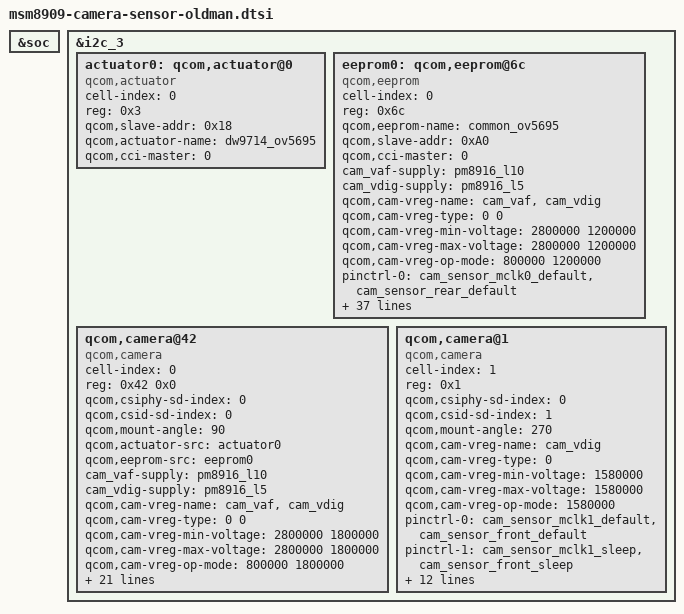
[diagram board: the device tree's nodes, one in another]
/*
 * Copyright (c) 2014-2015, The Linux Foundation. All rights reserved.
 *
 * This program is free software; you can redistribute it and/or modify
 * it under the terms of the GNU General Public License version 2 and
 * only version 2 as published by the Free Software Foundation.
 *
 * This program is distributed in the hope that it will be useful,
 * but WITHOUT ANY WARRANTY; without even the implied warranty of
 * MERCHANTABILITY or FITNESS FOR A PARTICULAR PURPOSE.  See the
 * GNU General Public License for more details.
 */

&soc {
};

&i2c_3 {

	actuator0: qcom,actuator@0 {
		cell-index = <0>;
		reg = <0x3>;
		qcom,slave-addr = <0x18>;
		compatible = "qcom,actuator";
		qcom,actuator-name = "dw9714_ov5695";
		qcom,cci-master = <0>;
	
	};

	eeprom0: qcom,eeprom@6c{
		cell-index = <0>;
		reg = <0x6c>;
		qcom,eeprom-name = "common_ov5695";
		compatible = "qcom,eeprom";
		qcom,slave-addr = <0xA0>;
		qcom,cci-master = <0>;	
			cam_vaf-supply = <&pm8916_l10>;
			cam_vdig-supply = <&pm8916_l5>; 	
			qcom,cam-vreg-name = "cam_vaf","cam_vdig";
			qcom,cam-vreg-type = <0  0>;
			qcom,cam-vreg-min-voltage = < 2800000 1200000 >;
			qcom,cam-vreg-max-voltage = < 2800000 1200000 >;
			qcom,cam-vreg-op-mode = <800000  1200000>;
			pinctrl-names = "cam_default", "cam_suspend";
			pinctrl-0 = <&cam_sensor_mclk0_default
					&cam_sensor_rear_default>;
			pinctrl-1 = <&cam_sensor_mclk0_sleep &cam_sensor_rear_sleep>;
			gpios = <&msm_gpio 26 0>,
				<&msm_gpio 35 0>,
				<&msm_gpio 34 0>,
				<&msm_gpio 99 0>,
				<&msm_gpio 16 0>,
				<&msm_gpio 17 0>;			
			qcom,gpio-reset = <1>;
			qcom,gpio-standby = <2>;
			qcom,gpio-vana = <3>;
			qcom,gpio-vdig = <4>;
			qcom,gpio-vio = <5>;		
			qcom,gpio-req-tbl-num = <0 1 2 3 4 5>;
			qcom,gpio-req-tbl-flags = <1 0 0 0 0 0>;
			qcom,gpio-req-tbl-label = "CAMIF_MCLK-eeprom",
				"CAM_RESET1",
				"CAM_STANDBY",
				"CAM_VANA",
				"CAM_VDIG",
				"CAM_VIO";		
		qcom,cam-power-seq-type = "sensor_gpio",
								     "sensor_gpio",
								     "sensor_gpio",
								     "sensor_vreg",
								     "sensor_gpio",
								     "sensor_vreg",
								     "sensor_clk",	
								     "sensor_gpio",
								     "sensor_gpio",
								     "sensor_gpio",
								     "sensor_i2c_mux";
		qcom,cam-power-seq-val ="sensor_gpio_reset",  
								"sensor_gpio_vio",
								"sensor_gpio_vdig",
							     "cam_vdig",
							     "sensor_gpio_vana",
							     "cam_vaf",
							     "sensor_cam_mclk",							     
							     "sensor_gpio_standby",
							      "sensor_gpio_standby",
		              			"sensor_gpio_reset",    
							     "none";		 
		qcom,cam-power-seq-cfg-val = < 0 1 1 1 1 1 0 24000000 0  1 1 0>;
		qcom,cam-power-seq-delay =   < 10 1 1  1 1 5 10 1 5 10 0>;
		zte,num-blocks = <6>;
		/*
		*   uint32_t valid_size;
			uint32_t addr;
			uint32_t addr_t;
			uint32_t data;
			uint32_t data_t;
			uint32_t delay;
		
		*/
		zte,mem0    = <30	 0xA0  2 0x0 1 0>;	
		zte,mem1    = <255	 0xA4  2 0x0 1 0>;  
		zte,mem2    = <255	 0xA6  2 0x0 1 0>; 
		zte,mem3    = <255	 0xA8  2 0x0 1 0>; 
		zte,mem4    = <255	 0xAA  2 0x0 1 0>; 
		zte,mem5    = <85	 0xAC  2 0x0 1 0>; 
		clocks = <&clock_gcc clk_mclk0_clk_src>,
				<&clock_gcc clk_gcc_camss_mclk0_clk>;
		clock-names = "cam_src_clk", "cam_clk";
		status = "ok";
	};
	#if 0
    /* add zte sensor dtsi for led-flash*/
	led_flash_zte0: qcom,led-flash@60 {
		cell-index = <0>;
		reg = <0x60>;
		qcom,slave-id = <0xc6 0x00 0x00>;
		compatible = "qcom,led-lm3642";
		label = "lm3642";
		qcom,flash-type = <1>;
		qcom,gpio-no-mux = <0>;
		qcom,enable_pinctrl;
		pinctrl-names = "cam_flash_default", "cam_flash_suspend";
		pinctrl-0 = <&cam_sensor_flash_default>;
		pinctrl-1 = <&cam_sensor_flash_sleep>;
		gpios = <&msm_gpio 82 0>,
			<&msm_gpio 70 0>;           /*32*/
		qcom,gpio-flash-en = <0>;
		qcom,gpio-flash-now = <1>;
		qcom,gpio-req-tbl-num = <0 1>;
		qcom,gpio-req-tbl-flags = <0 0>;
		qcom,gpio-req-tbl-label = "FLASH_EN",
			"FLASH_NOW";
		qcom,cci-master = <0>;
		status = "disabled";
	};
	#endif
	qcom,camera@42 {
			cell-index = <0>;
			compatible = "qcom,camera";
			reg = <0x42  0x0>;
			qcom,csiphy-sd-index = <0>;
			qcom,csid-sd-index = <0>;
			qcom,mount-angle = <90>;
			qcom,actuator-src = <&actuator0>;
			qcom,eeprom-src = <&eeprom0>;
			cam_vaf-supply = <&pm8916_l10>;
			cam_vdig-supply = <&pm8916_l5>; 	
			qcom,cam-vreg-name = "cam_vaf","cam_vdig";
			qcom,cam-vreg-type = <0  0>;
			qcom,cam-vreg-min-voltage = < 2800000 1800000 >;
			qcom,cam-vreg-max-voltage = < 2800000 1800000 >;
			qcom,cam-vreg-op-mode = <800000  1800000>;
			pinctrl-names = "cam_default", "cam_suspend";
			pinctrl-0 = <&cam_sensor_mclk0_default
					&cam_sensor_rear_default>;
			pinctrl-1 = <&cam_sensor_mclk0_sleep &cam_sensor_rear_sleep>;
			gpios = <&msm_gpio 26 0>,
				<&msm_gpio 35 0>,
				<&msm_gpio 34 0>,
				<&msm_gpio 99 0>,
				<&msm_gpio 16 0>,
				<&msm_gpio 17 0>;			
			qcom,gpio-reset = <1>;
			qcom,gpio-standby = <2>;
			qcom,gpio-vana = <3>;
			qcom,gpio-vdig = <4>;
			qcom,gpio-vio = <5>;		
			qcom,gpio-req-tbl-num = <0 1 2 3 4 5>;
			qcom,gpio-req-tbl-flags = <1 0 0 0 0 0>;
			qcom,gpio-req-tbl-label = "CAMIF_MCLK-camera",
				"CAM_RESET",
				"CAM_STANDBY",
				"CAM_VANA",
				"CAM_VDIG",
				"CAM_VIO";
			qcom,sensor-position = <0>;
			qcom,sensor-mode = <0>;
			qcom,cci-master = <0>;
			status = "ok";
			clocks = <&clock_gcc clk_mclk0_clk_src>,
					<&clock_gcc clk_gcc_camss_mclk0_clk>;
			clock-names = "cam_src_clk", "cam_clk";
		};
	
		qcom,camera@1 {
			cell-index = <1>;
			compatible = "qcom,camera";
			reg = <0x1>;
			qcom,csiphy-sd-index = <0>;
			qcom,csid-sd-index = <1>;
			qcom,mount-angle = <270>;						
			qcom,cam-vreg-name = "cam_vdig";								
			qcom,cam-vreg-type = <0  >;
			qcom,cam-vreg-min-voltage = < 1580000  >;
			qcom,cam-vreg-max-voltage = < 1580000  >;
			qcom,cam-vreg-op-mode = <1580000  >;		 	
			pinctrl-names = "cam_default", "cam_suspend";
			pinctrl-0 = <&cam_sensor_mclk1_default &cam_sensor_front_default>;
			pinctrl-1 = <&cam_sensor_mclk1_sleep &cam_sensor_front_sleep>;
			gpios = <&msm_gpio 27 0>,
				<&msm_gpio 28 0>,
				<&msm_gpio 99 0>,
				<&msm_gpio 17 0>;
			qcom,gpio-reset = <1>;
			qcom,gpio-vana = <2>;
			qcom,gpio-vio = <3>;
			qcom,gpio-req-tbl-num = <0 1 2 3>;
			qcom,gpio-req-tbl-flags = <1 0 0 0>;
			qcom,gpio-req-tbl-label = "CAMIF_MCLK-camera2",
				"CAM_RESET",
				"CAM_VANA",
				"CAM_VIO";
			qcom,cci-master = <0>;
			status = "ok";
			clocks = <&clock_gcc clk_mclk1_clk_src>,
					<&clock_gcc clk_gcc_camss_mclk1_clk>;
			clock-names = "cam_src_clk", "cam_clk";
		};



	
};
